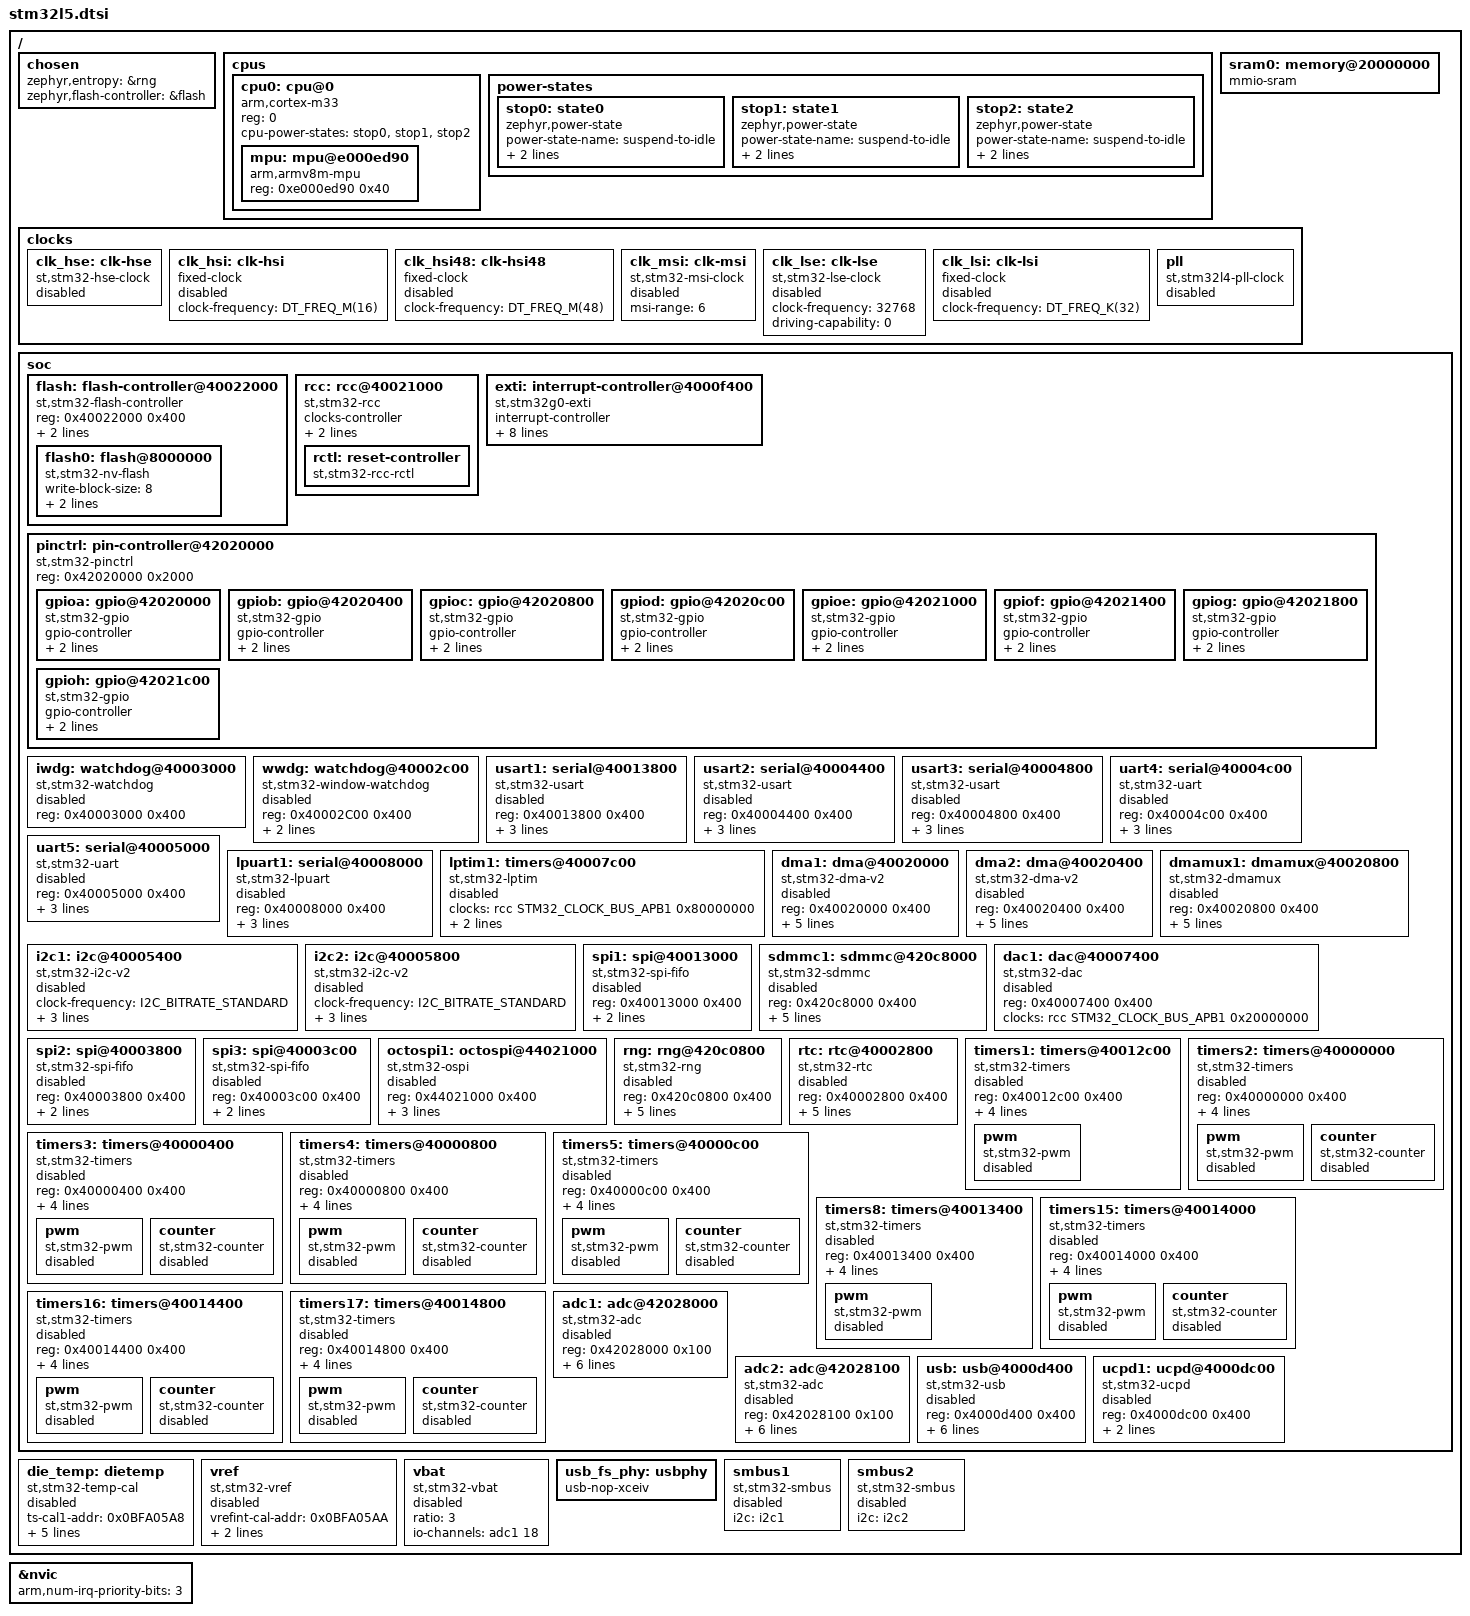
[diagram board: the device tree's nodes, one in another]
/*
 * Copyright (c) 2021 The Chromium OS Authors
 * Copyright (c) 2020 Linaro Limited
 * Copyright (c) 2024 STMicroelectronics
 *
 * SPDX-License-Identifier: Apache-2.0
 */


#include <arm/armv8-m.dtsi>
#include <zephyr/dt-bindings/clock/stm32l4_clock.h>
#include <zephyr/dt-bindings/gpio/gpio.h>
#include <zephyr/dt-bindings/i2c/i2c.h>
#include <zephyr/dt-bindings/pwm/pwm.h>
#include <zephyr/dt-bindings/pwm/stm32_pwm.h>
#include <zephyr/dt-bindings/dma/stm32_dma.h>
#include <zephyr/dt-bindings/adc/stm32l4_adc.h>
#include <zephyr/dt-bindings/reset/stm32g4_l4_5_reset.h>
#include <zephyr/dt-bindings/adc/adc.h>
#include <zephyr/dt-bindings/flash_controller/ospi.h>
#include <freq.h>

/ {
	chosen {
		zephyr,entropy = &rng;
		zephyr,flash-controller = &flash;
	};

	cpus {
		#address-cells = <1>;
		#size-cells = <0>;

		cpu0: cpu@0 {
			device_type = "cpu";
			compatible = "arm,cortex-m33";
			reg = <0>;
			#address-cells = <1>;
			#size-cells = <1>;
			cpu-power-states = <&stop0 &stop1 &stop2>;

			mpu: mpu@e000ed90 {
				compatible = "arm,armv8m-mpu";
				reg = <0xe000ed90 0x40>;
			};
		};

		power-states {
			stop0: state0 {
				compatible = "zephyr,power-state";
				power-state-name = "suspend-to-idle";
				substate-id = <1>;
				min-residency-us = <100>;
			};
			stop1: state1 {
				compatible = "zephyr,power-state";
				power-state-name = "suspend-to-idle";
				substate-id = <2>;
				min-residency-us = <500>;
			};
			stop2: state2 {
				compatible = "zephyr,power-state";
				power-state-name = "suspend-to-idle";
				substate-id = <3>;
				min-residency-us = <900>;
			};
		};
	};

	sram0: memory@20000000 {
		compatible = "mmio-sram";
	};

	clocks {
		clk_hse: clk-hse {
			#clock-cells = <0>;
			compatible = "st,stm32-hse-clock";
			status = "disabled";
		};

		clk_hsi: clk-hsi {
			#clock-cells = <0>;
			compatible = "fixed-clock";
			clock-frequency = <DT_FREQ_M(16)>;
			status = "disabled";
		};

		clk_hsi48: clk-hsi48 {
			#clock-cells = <0>;
			compatible = "fixed-clock";
			clock-frequency = <DT_FREQ_M(48)>;
			status = "disabled";
		};

		clk_msi: clk-msi {
			#clock-cells = <0>;
			compatible = "st,stm32-msi-clock";
			msi-range = <6>; /* 4MHz (reset value) */
			status = "disabled";
		};

		clk_lse: clk-lse {
			#clock-cells = <0>;
			compatible = "st,stm32-lse-clock";
			clock-frequency = <32768>;
			driving-capability = <0>;
			status = "disabled";
		};

		clk_lsi: clk-lsi {
			#clock-cells = <0>;
			compatible = "fixed-clock";
			clock-frequency = <DT_FREQ_K(32)>;
			status = "disabled";
		};

		pll: pll {
			#clock-cells = <0>;
			compatible = "st,stm32l4-pll-clock";
			status = "disabled";
		};
	};

	soc {
		flash: flash-controller@40022000 {
			compatible = "st,stm32-flash-controller", "st,stm32l5-flash-controller";
			reg = <0x40022000 0x400>;
			interrupts = <6 0>;
			clocks = <&rcc STM32_CLOCK_BUS_AHB1 0x00000100>;

			#address-cells = <1>;
			#size-cells = <1>;

			flash0: flash@8000000 {
				compatible = "st,stm32-nv-flash", "soc-nv-flash";
				write-block-size = <8>;
				erase-block-size = <2048>;

				/* using maximum erase time(ms) for 4K page, since
				 * datasheet does not show the maximum erase
				 * for a 2K(dual-bank) page.
				 */
				max-erase-time = <25>;
			};
		};

		rcc: rcc@40021000 {
			compatible = "st,stm32-rcc";
			clocks-controller;
			#clock-cells = <2>;
			reg = <0x40021000 0x400>;
			undershoot-prevention;

			rctl: reset-controller {
				compatible = "st,stm32-rcc-rctl";
				#reset-cells = <1>;
			};
		};

		exti: interrupt-controller@4000f400 {
			compatible = "st,stm32g0-exti", "st,stm32-exti";
			interrupt-controller;
			#interrupt-cells = <1>;
			reg = <0x4000f400 0x400>;
			num-lines = <16>;
			interrupts = <11 0>, <12 0>, <13 0>, <14 0>,
				     <15 0>, <16 0>, <17 0>, <18 0>,
				     <19 0>, <20 0>, <21 0>, <22 0>,
				     <23 0>, <24 0>, <25 0>, <26 0>;
			interrupt-names = "line0", "line1", "line2", "line3",
					  "line4", "line5", "line6", "line7",
					  "line8", "line9", "line10", "line11",
					  "line12", "line13", "line14", "line15";
			line-ranges = <0 1>, <1 1>, <2 1>, <3 1>,
				      <4 1>, <5 1>, <6 1>, <7 1>,
				      <8 1>, <9 1>, <10 1>, <11 1>,
				      <12 1>, <13 1>, <14 1>, <15 1>;
		};

		pinctrl: pin-controller@42020000 {
			compatible = "st,stm32-pinctrl";
			#address-cells = <1>;
			#size-cells = <1>;
			reg = <0x42020000 0x2000>;

			gpioa: gpio@42020000 {
				compatible = "st,stm32-gpio";
				gpio-controller;
				#gpio-cells = <2>;
				reg = <0x42020000 0x400>;
				clocks = <&rcc STM32_CLOCK_BUS_AHB2 0x00000001>;
			};

			gpiob: gpio@42020400 {
				compatible = "st,stm32-gpio";
				gpio-controller;
				#gpio-cells = <2>;
				reg = <0x42020400 0x400>;
				clocks = <&rcc STM32_CLOCK_BUS_AHB2 0x00000002>;
			};

			gpioc: gpio@42020800 {
				compatible = "st,stm32-gpio";
				gpio-controller;
				#gpio-cells = <2>;
				reg = <0x42020800 0x400>;
				clocks = <&rcc STM32_CLOCK_BUS_AHB2 0x00000004>;
			};

			gpiod: gpio@42020c00 {
				compatible = "st,stm32-gpio";
				gpio-controller;
				#gpio-cells = <2>;
				reg = <0x42020c00 0x400>;
				clocks = <&rcc STM32_CLOCK_BUS_AHB2 0x00000008>;
			};

			gpioe: gpio@42021000 {
				compatible = "st,stm32-gpio";
				gpio-controller;
				#gpio-cells = <2>;
				reg = <0x42021000 0x400>;
				clocks = <&rcc STM32_CLOCK_BUS_AHB2 0x00000010>;
			};

			gpiof: gpio@42021400 {
				compatible = "st,stm32-gpio";
				gpio-controller;
				#gpio-cells = <2>;
				reg = <0x42021400 0x400>;
				clocks = <&rcc STM32_CLOCK_BUS_AHB2 0x00000020>;
			};

			gpiog: gpio@42021800 {
				compatible = "st,stm32-gpio";
				gpio-controller;
				#gpio-cells = <2>;
				reg = <0x42021800 0x400>;
				clocks = <&rcc STM32_CLOCK_BUS_AHB2 0x00000040>;
			};

			gpioh: gpio@42021c00 {
				compatible = "st,stm32-gpio";
				gpio-controller;
				#gpio-cells = <2>;
				reg = <0x42021c00 0x400>;
				clocks = <&rcc STM32_CLOCK_BUS_AHB2 0x00000080>;
			};
		};

		iwdg: watchdog@40003000 {
			compatible = "st,stm32-watchdog";
			reg = <0x40003000 0x400>;
			status = "disabled";
		};

		wwdg: watchdog@40002c00 {
			compatible = "st,stm32-window-watchdog";
			reg = <0x40002C00 0x400>;
			clocks = <&rcc STM32_CLOCK_BUS_APB1 0x00000800>;
			interrupts = <0 6>;
			status = "disabled";
		};

		usart1: serial@40013800 {
			compatible = "st,stm32-usart", "st,stm32-uart";
			reg = <0x40013800 0x400>;
			clocks = <&rcc STM32_CLOCK_BUS_APB2 0x00004000>;
			resets = <&rctl STM32_RESET(APB2, 14U)>;
			interrupts = <61 0>;
			status = "disabled";
		};

		usart2: serial@40004400 {
			compatible = "st,stm32-usart", "st,stm32-uart";
			reg = <0x40004400 0x400>;
			clocks = <&rcc STM32_CLOCK_BUS_APB1 0x00020000>;
			resets = <&rctl STM32_RESET(APB1L, 17U)>;
			interrupts = <62 0>;
			status = "disabled";
		};

		usart3: serial@40004800 {
			compatible = "st,stm32-usart", "st,stm32-uart";
			reg = <0x40004800 0x400>;
			clocks = <&rcc STM32_CLOCK_BUS_APB1 0x00040000>;
			resets = <&rctl STM32_RESET(APB1L, 18U)>;
			interrupts = <63 0>;
			status = "disabled";
		};

		uart4: serial@40004c00 {
			compatible = "st,stm32-uart";
			reg = <0x40004c00 0x400>;
			clocks = <&rcc STM32_CLOCK_BUS_APB1 0x00080000>;
			resets = <&rctl STM32_RESET(APB1L, 19U)>;
			interrupts = <64 0>;
			status = "disabled";
		};

		uart5: serial@40005000 {
			compatible = "st,stm32-uart";
			reg = <0x40005000 0x400>;
			clocks = <&rcc STM32_CLOCK_BUS_APB1 0x00100000>;
			resets = <&rctl STM32_RESET(APB1L, 20U)>;
			interrupts = <65 0>;
			status = "disabled";
		};

		lpuart1: serial@40008000 {
			compatible = "st,stm32-lpuart", "st,stm32-uart";
			reg = <0x40008000 0x400>;
			clocks = <&rcc STM32_CLOCK_BUS_APB1_2 0x00000001>;
			resets = <&rctl STM32_RESET(APB1H, 0U)>;
			interrupts = <66 0>;
			status = "disabled";
		};

		lptim1: timers@40007c00 {
			compatible = "st,stm32-lptim";
			clocks = <&rcc STM32_CLOCK_BUS_APB1 0x80000000>;
			#address-cells = <1>;
			#size-cells = <0>;
			reg = <0x40007c00 0x400>;
			interrupts = <67 1>;
			interrupt-names = "wakeup";
			status = "disabled";
		};

		dma1: dma@40020000 {
			compatible = "st,stm32-dma-v2";
			#dma-cells = <3>;
			reg = <0x40020000 0x400>;
			interrupts = <29 0 30 0 31 0 32 0 33 0 34 0 35 0 36 0>;
			clocks = <&rcc STM32_CLOCK_BUS_AHB1 0x1>;
			dma-requests = <8>;
			dma-offset = <0>;
			status = "disabled";
		};

		dma2: dma@40020400 {
			compatible = "st,stm32-dma-v2";
			#dma-cells = <3>;
			reg = <0x40020400 0x400>;
			interrupts = <80 0 81 0 82 0 83 0 84 0 85 0 86 0 87 0>;
			clocks = <&rcc STM32_CLOCK_BUS_AHB1 0x2>;
			dma-requests = <8>;
			dma-offset = <8>;
			status = "disabled";
		};

		dmamux1: dmamux@40020800 {
			compatible = "st,stm32-dmamux";
			#dma-cells = <3>;
			reg = <0x40020800 0x400>;
			interrupts = <27 0>;
			clocks = <&rcc STM32_CLOCK_BUS_AHB1 0x4>;
			dma-channels = <16>;
			dma-generators = <4>;
			dma-requests= <90>;
			status = "disabled";
		};

		i2c1: i2c@40005400 {
			compatible = "st,stm32-i2c-v2";
			clock-frequency = <I2C_BITRATE_STANDARD>;
			#address-cells = <1>;
			#size-cells = <0>;
			reg = <0x40005400 0x400>;
			clocks = <&rcc STM32_CLOCK_BUS_APB1 0x00200000>;
			interrupts = <55 0>, <56 0>;
			interrupt-names = "event", "error";
			status = "disabled";
		};

		i2c2: i2c@40005800 {
			compatible = "st,stm32-i2c-v2";
			#address-cells = <1>;
			#size-cells = <0>;
			clock-frequency = <I2C_BITRATE_STANDARD>;
			reg = <0x40005800 0x400>;
			clocks = <&rcc STM32_CLOCK_BUS_APB1 0x00400000>;
			interrupts = <57 0>, <58 0>;
			interrupt-names = "event", "error";
			status = "disabled";
		};

		spi1: spi@40013000 {
			compatible = "st,stm32-spi-fifo", "st,stm32-spi";
			#address-cells = <1>;
			#size-cells = <0>;
			reg = <0x40013000 0x400>;
			interrupts = <59 5>;
			clocks = <&rcc STM32_CLOCK_BUS_APB2 0x00001000>;
			status = "disabled";
		};

		sdmmc1: sdmmc@420c8000 {
			compatible = "st,stm32-sdmmc";
			reg = <0x420c8000 0x400>;
			clocks = <&rcc STM32_CLOCK_BUS_AHB2 0x00400000>,
				 <&rcc STM32_SRC_HSI48 SDMMC_SEL(0)>;
			resets = <&rctl STM32_RESET(AHB2, 22U)>;
			interrupts = <78 0>;
			status = "disabled";
			disk-name = "SDMMC";
		};

		dac1: dac@40007400 {
			compatible = "st,stm32-dac";
			reg = <0x40007400 0x400>;
			clocks = <&rcc STM32_CLOCK_BUS_APB1 0x20000000>;
			status = "disabled";
			#io-channel-cells = <1>;
		};

		spi2: spi@40003800 {
			compatible = "st,stm32-spi-fifo", "st,stm32-spi";
			#address-cells = <1>;
			#size-cells = <0>;
			reg = <0x40003800 0x400>;
			interrupts = <60 5>;
			clocks = <&rcc STM32_CLOCK_BUS_APB1 0x00004000>;
			status = "disabled";
		};

		spi3: spi@40003c00 {
			compatible = "st,stm32-spi-fifo", "st,stm32-spi";
			#address-cells = <1>;
			#size-cells = <0>;
			reg = <0x40003c00 0x400>;
			interrupts = <99 5>;
			clocks = <&rcc STM32_CLOCK_BUS_APB1 0x00008000>;
			status = "disabled";
		};

		octospi1: octospi@44021000 {
			compatible = "st,stm32-ospi";
			reg = <0x44021000 0x400>;
			interrupts = <76 0>;
			clock-names = "ospix", "ospi-ker";
			clocks = <&rcc STM32_CLOCK_BUS_AHB3 0x00000100>,
					<&rcc STM32_SRC_SYSCLK OSPI_SEL(0)>;
			#address-cells = <1>;
			#size-cells = <0>;
			status = "disabled";
		};

		rng: rng@420c0800 {
			compatible = "st,stm32-rng";
			reg = <0x420c0800 0x400>;
			interrupts = <94 0>;
			clocks = <&rcc STM32_CLOCK_BUS_AHB2 0x00040000>;
			nist-config = <0xf00d00>;
			health-test-magic = <0x17590abc>;
			health-test-config = <0xa2b3>;
			status = "disabled";
		};

		rtc: rtc@40002800 {
			compatible = "st,stm32-rtc";
			reg = <0x40002800 0x400>;
			interrupts = <2 0>;
			clocks = <&rcc STM32_CLOCK_BUS_APB1 0x00000400>;
			prescaler = <32768>;
			alarms-count = <2>;
			alrm-exti-line = <17>;
			status = "disabled";
		};

		timers1: timers@40012c00 {
			compatible = "st,stm32-timers";
			reg = <0x40012c00 0x400>;
			clocks = <&rcc STM32_CLOCK_BUS_APB2 0x00000800>;
			resets = <&rctl STM32_RESET(APB2, 11U)>;
			interrupts = <41 0>, <42 0>, <43 0>, <44 0>;
			interrupt-names = "brk", "up", "trgcom", "cc";
			st,prescaler = <0>;
			status = "disabled";

			pwm {
				compatible = "st,stm32-pwm";
				status = "disabled";
				#pwm-cells = <3>;
			};
		};

		timers2: timers@40000000 {
			compatible = "st,stm32-timers";
			reg = <0x40000000 0x400>;
			clocks = <&rcc STM32_CLOCK_BUS_APB1 0x00000001>;
			resets = <&rctl STM32_RESET(APB1L, 0U)>;
			interrupts = <45 0>;
			interrupt-names = "global";
			st,prescaler = <0>;
			status = "disabled";

			pwm {
				compatible = "st,stm32-pwm";
				status = "disabled";
				#pwm-cells = <3>;
			};

			counter {
				compatible = "st,stm32-counter";
				status = "disabled";
			};
		};

		timers3: timers@40000400 {
			compatible = "st,stm32-timers";
			reg = <0x40000400 0x400>;
			clocks = <&rcc STM32_CLOCK_BUS_APB1 0x00000002>;
			resets = <&rctl STM32_RESET(APB1L, 1U)>;
			interrupts = <46 0>;
			interrupt-names = "global";
			st,prescaler = <0>;
			status = "disabled";

			pwm {
				compatible = "st,stm32-pwm";
				status = "disabled";
				#pwm-cells = <3>;
			};

			counter {
				compatible = "st,stm32-counter";
				status = "disabled";
			};
		};

		timers4: timers@40000800 {
			compatible = "st,stm32-timers";
			reg = <0x40000800 0x400>;
			clocks = <&rcc STM32_CLOCK_BUS_APB1 0x00000004>;
			resets = <&rctl STM32_RESET(APB1L, 2U)>;
			interrupts = <47 0>;
			interrupt-names = "global";
			st,prescaler = <0>;
			status = "disabled";

			pwm {
				compatible = "st,stm32-pwm";
				status = "disabled";
				#pwm-cells = <3>;
			};

			counter {
				compatible = "st,stm32-counter";
				status = "disabled";
			};
		};

		timers5: timers@40000c00 {
			compatible = "st,stm32-timers";
			reg = <0x40000c00 0x400>;
			clocks = <&rcc STM32_CLOCK_BUS_APB1 0x00000008>;
			resets = <&rctl STM32_RESET(APB1L, 3U)>;
			interrupts = <48 0>;
			interrupt-names = "global";
			st,prescaler = <0>;
			status = "disabled";

			pwm {
				compatible = "st,stm32-pwm";
				status = "disabled";
				#pwm-cells = <3>;
			};

			counter {
				compatible = "st,stm32-counter";
				status = "disabled";
			};
		};

		timers8: timers@40013400 {
			compatible = "st,stm32-timers";
			reg = <0x40013400 0x400>;
			clocks = <&rcc STM32_CLOCK_BUS_APB2 0x00002000>;
			resets = <&rctl STM32_RESET(APB2, 13U)>;
			interrupts = <51 0>, <52 0>, <53 0>, <54 0>;
			interrupt-names = "brk", "up", "trgcom", "cc";
			st,prescaler = <0>;
			status = "disabled";

			pwm {
				compatible = "st,stm32-pwm";
				status = "disabled";
				#pwm-cells = <3>;
			};
		};

		timers15: timers@40014000 {
			compatible = "st,stm32-timers";
			reg = <0x40014000 0x400>;
			clocks = <&rcc STM32_CLOCK_BUS_APB2 0x00010000>;
			resets = <&rctl STM32_RESET(APB2, 16U)>;
			interrupts = <69 0>;
			interrupt-names = "global";
			st,prescaler = <0>;
			status = "disabled";

			pwm {
				compatible = "st,stm32-pwm";
				status = "disabled";
				#pwm-cells = <3>;
			};

			counter {
				compatible = "st,stm32-counter";
				status = "disabled";
			};
		};

		timers16: timers@40014400 {
			compatible = "st,stm32-timers";
			reg = <0x40014400 0x400>;
			clocks = <&rcc STM32_CLOCK_BUS_APB2 0x00020000>;
			resets = <&rctl STM32_RESET(APB2, 17U)>;
			interrupts = <70 0>;
			interrupt-names = "global";
			st,prescaler = <0>;
			status = "disabled";

			pwm {
				compatible = "st,stm32-pwm";
				status = "disabled";
				#pwm-cells = <3>;
			};

			counter {
				compatible = "st,stm32-counter";
				status = "disabled";
			};
		};

		timers17: timers@40014800 {
			compatible = "st,stm32-timers";
			reg = <0x40014800 0x400>;
			clocks = <&rcc STM32_CLOCK_BUS_APB2 0x00040000>;
			resets = <&rctl STM32_RESET(APB2, 18U)>;
			interrupts = <71 0>;
			interrupt-names = "global";
			st,prescaler = <0>;
			status = "disabled";

			pwm {
				compatible = "st,stm32-pwm";
				status = "disabled";
				#pwm-cells = <3>;
			};

			counter {
				compatible = "st,stm32-counter";
				status = "disabled";
			};
		};

		adc1: adc@42028000 {
			compatible = "st,stm32-adc";
			reg = <0x42028000 0x100>;
			clocks = <&rcc STM32_CLOCK_BUS_AHB2 0x00002000>;
			interrupts = <37 0>;
			status = "disabled";
			#io-channel-cells = <1>;
			resolutions = <STM32_ADC_RES(12, 0x00)
				       STM32_ADC_RES(10, 0x01)
				       STM32_ADC_RES(8, 0x02)
				       STM32_ADC_RES(6, 0x03)>;
			sampling-times = <3 7 13 25 48 93 248 641>;
			st,adc-sequencer = <FULLY_CONFIGURABLE>;
		};

		adc2: adc@42028100 {
			compatible = "st,stm32-adc";
			reg = <0x42028100 0x100>;
			clocks = <&rcc STM32_CLOCK_BUS_AHB2 0x00002000>;
			interrupts = <37 0>;
			status = "disabled";
			#io-channel-cells = <1>;
			resolutions = <STM32_ADC_RES(12, 0x00)
				       STM32_ADC_RES(10, 0x01)
				       STM32_ADC_RES(8, 0x02)
				       STM32_ADC_RES(6, 0x03)>;
			sampling-times = <3 7 13 25 48 93 248 641>;
			st,adc-sequencer = <FULLY_CONFIGURABLE>;
		};

		usb: usb@4000d400 {
			compatible = "st,stm32-usb";
			reg = <0x4000d400 0x400>;
			interrupts = <73 0>;
			interrupt-names = "usb";
			num-bidir-endpoints = <8>;
			ram-size = <1024>;
			status = "disabled";
			clocks = <&rcc STM32_CLOCK_BUS_APB1_2 0x00200000>,
				 <&rcc STM32_SRC_HSI48 CLK48_SEL(0)>;
			phys = <&usb_fs_phy>;
		};

		ucpd1: ucpd@4000dc00 {
			compatible = "st,stm32-ucpd";
			reg = <0x4000dc00 0x400>;
			clocks = <&rcc STM32_CLOCK_BUS_APB1 0x00800000>;
			interrupts = <106 0>;
			status = "disabled";
		};
	};

	die_temp: dietemp {
		compatible = "st,stm32-temp-cal";
		ts-cal1-addr = <0x0BFA05A8>;
		ts-cal2-addr = <0x0BFA05CA>;
		ts-cal1-temp = <30>;
		ts-cal2-temp = <130>;
		ts-cal-vrefanalog = <3000>;
		io-channels = <&adc1 17>;
		status = "disabled";
	};

	vref: vref {
		compatible = "st,stm32-vref";
		vrefint-cal-addr = <0x0BFA05AA>;
		vrefint-cal-mv = <3000>;
		io-channels = <&adc1 0>;
		status = "disabled";
	};

	vbat: vbat {
		compatible = "st,stm32-vbat";
		ratio = <3>;
		io-channels = <&adc1 18>;
		status = "disabled";
	};

	usb_fs_phy: usbphy {
		compatible = "usb-nop-xceiv";
		#phy-cells = <0>;
	};

	smbus1: smbus1 {
		compatible = "st,stm32-smbus";
		#address-cells = <1>;
		#size-cells = <0>;
		i2c = <&i2c1>;
		status = "disabled";
	};

	smbus2: smbus2 {
		compatible = "st,stm32-smbus";
		#address-cells = <1>;
		#size-cells = <0>;
		i2c = <&i2c2>;
		status = "disabled";
	};

};

&nvic {
	arm,num-irq-priority-bits = <3>;
};
